# BL808 register map
File version: 0.1
Registers are access not given, no defined reset value unless marked. A register's access mark holds for its fields unless they carry their own. Offsets are from the block's base; [hi:lo] are bit positions; {n}, {i} and the like mark numbered series; 'fields as' and 'values as' point back to an identical list; <NAME> marks a mode.

## DMA2
Base 0x30001000
Same registers: DMA0 0x2000C000, DMA1 0x20071000
0x00 DMA_IntStatus
  [7:0] IntStatus ro — Status of the DMA interrupts after masking
0x04 DMA_IntTCStatus
  [7:0] IntTCStatus ro — Interrupt terminal count request status
0x08 DMA_IntTCClear
  [7:0] IntTCClear wo — Terminal count request clear
0x0C DMA_IntErrorStatus
  [7:0] IntErrorStatus ro — Interrupt error status
0x10 DMA_IntErrClr
  [7:0] IntErrClr wo — Interrupt error clear
0x14 DMA_RawIntTCStatus
  [7:0] RawIntTCStatus ro — Status of the terminal count interrupt prior to masking
0x18 DMA_RawIntErrorStatus
  [7:0] RawIntErrorStatus ro — Status of the error interrupt prior to masking
0x1C DMA_EnbldChns
  [7:0] EnabledChannels ro — Channel enable status
0x20 DMA_SoftBReq rw
  [31:0] SoftBReq — Software burst request
0x24 DMA_SoftSReq rw
  [31:0] SoftSReq — Software single request
0x28 DMA_SoftLBReq rw
  [31:0] SoftLBReq — Software last burst request
0x2C DMA_SoftLSReq rw
  [31:0] SoftLSReq — Software last single request
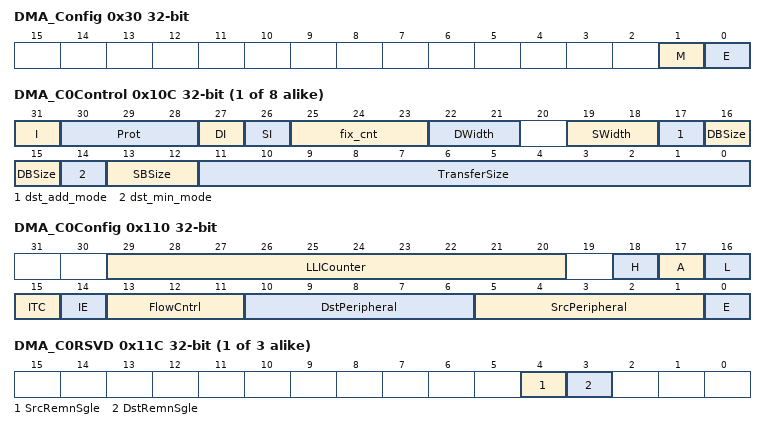
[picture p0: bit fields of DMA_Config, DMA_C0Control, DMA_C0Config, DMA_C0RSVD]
0x30 DMA_Config
  [1] M rw — AHB Master endianness configuration: 0 = little-endian, 1 = big-endian
  [0] E rw — SMDMA Enable.
0x34 DMA_Sync rw
  [31:0] DMA_Sync — DMA synchronization logic for DMA request signals: 0 = enable, 1 = disable
0x100 DMA_C0SrcAddr rw
  [31:0] SrcAddr — DMA source address
0x104 DMA_C0DstAddr rw
  [31:0] DstAddr — DMA Destination address
0x108 DMA_C0LLI rw
  [31:0] LLI — First linked list item. Bits [1:0] must be 0.
{0x10C+0x100*i} DMA_C{i}Control (i=0..7)
  [31] I rw — Terminal count interrupt enable bit. It controls whether the current LLI is expected to trigger the terminal count interrupt.
  [30:28] Prot rw — No use for currently
  [27] DI rw — Destination increment. When set, the Destination address is incremented after each transfer.
  [26] SI rw — Source increment. When set, the source address is incremented after each transfer.
  [25:23] fix_cnt rw — Only effect when dst_min_mode = 1 Destination transfer cnt = (total src byte cnt - (fix_cnt<<DWidth))<<DWidth
  [22:21] DWidth rw — Destination transfer width: 2'b00 : byte 2'b01 : half-word 2'b10 : word 2'b11 : double-word
  [19:18] SWidth rw — Source transfer width 2'b00 : byte 2'b01 : half-word 2'b10 : word 2'b11 : double-word
  [17] dst_add_mode rw — Add mode : issue remain destination traffic
  [16:15] DBSize rw — Destination burst size 2'b00 : INCR1 2'b01 : INCR4 2'b10 : INCR8 2'b11 : INCR16 Note : SBSize*Swidth should <= CH FIFO Size
  [14] dst_min_mode rw — Minus mode : Not issue all destination traffic
  [13:12] SBSize rw — Source burst size: 2'b00 : INCR1 2'b01 : INCR4 2'b10 : INCR8 2'b11 : INCR16 Note : SBSize*Swidth should <= CH FIFO Size
  [11:0] TransferSize rw — Transfer size: 0~4095. Number of data transfers left to complete when the SMDMA is the flow controller.
0x110 DMA_C0Config
  [29:20] LLICounter ro — LLI counter. Increased 1 each LLI run. Cleared 0 when config Control.
  [18] H rw — Halt: 0 = enable DMA requests, 1 = ignore subsequent source DMA requests.
  [17] A ro — Active: 0 = no data in FIFO of the channel, 1 = FIFO of the channel has data.
  [16] L rw — Lock.
  [15] ITC rw — Terminal count interrupt mask.
  [14] IE rw — Interrupt error mask.
  [13:11] FlowCntrl rw — 000: Memory-to-memory (DMA) 001: Memory-to-peripheral (DMA) 010: Peripheral-to-memory (DMA) 011: Source peripheral-to-Destination peripheral (DMA) 100: Source peripheral-to-Destination peripheral (Destination peripheral) 101: Memory-to-peripheral (peripheral) 110: Peripheral-to-memory (peripheral) 111: Source peripheral-to-Destination peripheral (Source peripheral)
  [10:6] DstPeripheral rw — Destination peripheral.
  [5:1] SrcPeripheral rw — Source peripheral.
  [0] E rw — Channel enable.
{0x11C+0x100*i} DMA_C{i}RSVD (i=0..2)
  [4] SrcRemnSgle rw — Source remain single issue mode
  [3] DstRemnSgle rw — Destination remain single issue mode
{0x100+0x100*i} DMA_C{i}SrcAddr rw (i=1..7)
  [31:0] SrcAddr
{0x104+0x100*i} DMA_C{i}DstAddr rw (i=1..7)
  [31:0] DstAddr
{0x108+0x100*i} DMA_C{i}LLI rw (i=1..7)
  [31:0] LLI
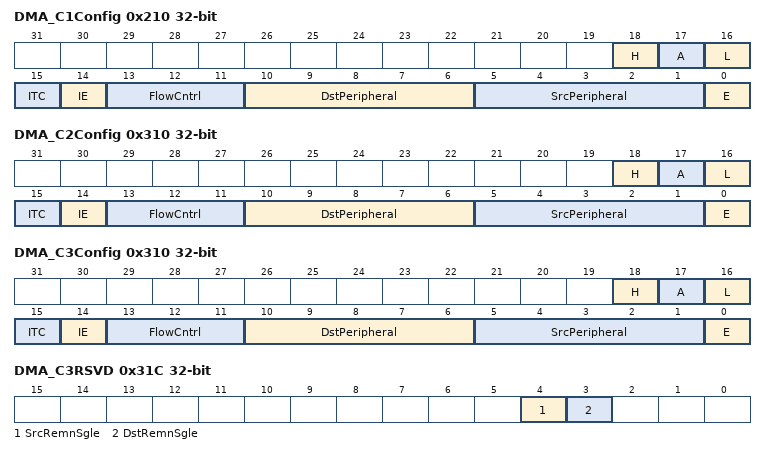
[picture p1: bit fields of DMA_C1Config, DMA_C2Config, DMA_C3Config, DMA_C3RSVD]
0x210 DMA_C1Config
  [18] H rw, [17] A ro, [16] L rw, [15] ITC rw, [14] IE rw, [13:11] FlowCntrl rw, [10:6] DstPeripheral rw, [5:1] SrcPeripheral rw, [0] E rw
0x310 DMA_C2Config
  fields as DMA_C1Config
0x310 DMA_C3Config
  fields as DMA_C1Config
0x31C DMA_C3RSVD
  fields as DMA_C0RSVD
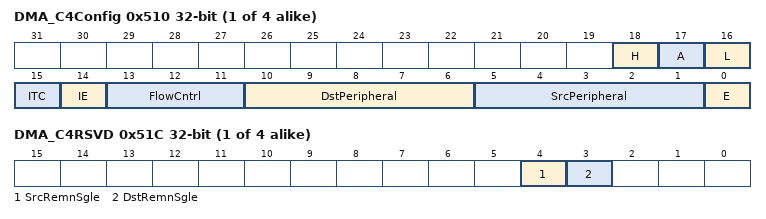
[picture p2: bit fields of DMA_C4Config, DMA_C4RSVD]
{0x110+0x100*i} DMA_C{i}Config (i=4..7)
  fields as DMA_C1Config
{0x11C+0x100*i} DMA_C{i}RSVD (i=4..7)
  fields as DMA_C0RSVD
